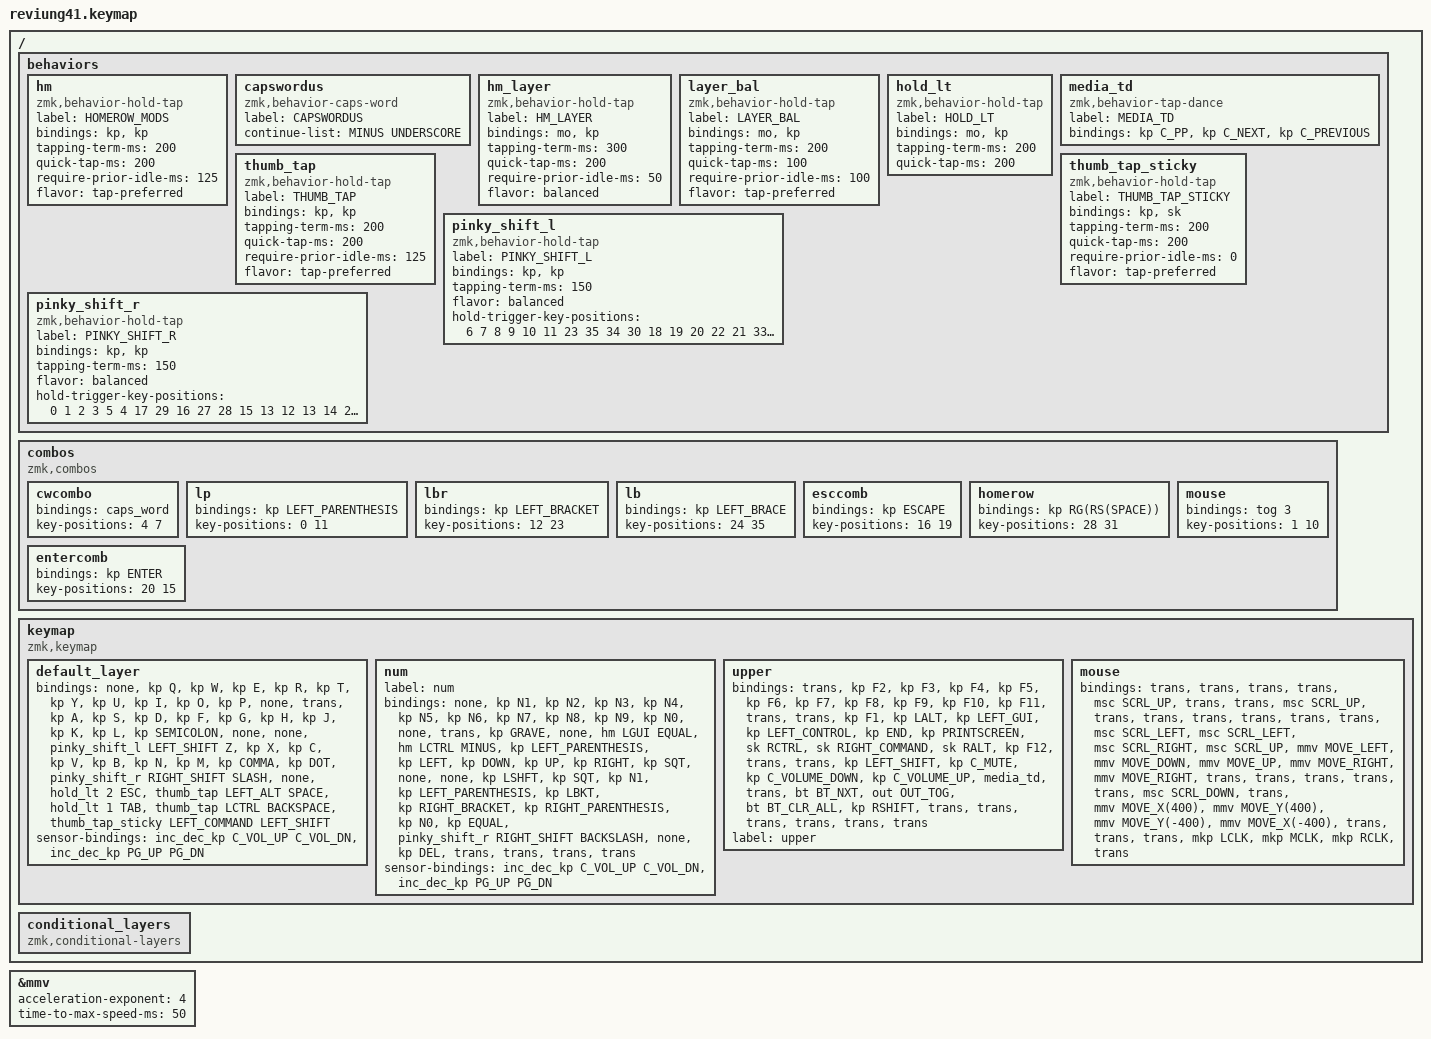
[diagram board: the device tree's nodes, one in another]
/*
 * Copyright (c) 2020 The ZMK Contributors
 *
 * SPDX-License-Identifier: MIT
 */

#define ZMK_POINTING_DEFAULT_MOVE_VAL 1500  // default: 600
#define ZMK_POINTING_DEFAULT_SCRL_VAL 20    // default: 10

#include <behaviors.dtsi>
#include <dt-bindings/zmk/bt.h>
#include <dt-bindings/zmk/keys.h>
#include <dt-bindings/zmk/outputs.h>
#include <dt-bindings/zmk/pointing.h>

&mmv {
    acceleration-exponent = <4>;
    time-to-max-speed-ms = <50>;
};

/ {
    behaviors {
        hm: hm {
            compatible = "zmk,behavior-hold-tap";
            label = "HOMEROW_MODS";
            bindings = <&kp>, <&kp>;

            #binding-cells = <2>;
            tapping-term-ms = <200>;
            quick-tap-ms = <200>;
            require-prior-idle-ms = <125>;
            flavor = "tap-preferred";
        };

        capswordus: capswordus {
            compatible = "zmk,behavior-caps-word";
            label = "CAPSWORDUS";
            #binding-cells = <0>;
            continue-list = <MINUS UNDERSCORE>;
        };

        hm_layer: hm_layer {
            compatible = "zmk,behavior-hold-tap";
            label = "HM_LAYER";
            bindings = <&mo>, <&kp>;

            #binding-cells = <2>;
            tapping-term-ms = <300>;
            quick-tap-ms = <200>;
            require-prior-idle-ms = <50>;
            flavor = "balanced";
        };

        layer_bal: layer_bal {
            compatible = "zmk,behavior-hold-tap";
            label = "LAYER_BAL";
            bindings = <&mo>, <&kp>;

            #binding-cells = <2>;
            tapping-term-ms = <200>;
            quick-tap-ms = <100>;
            require-prior-idle-ms = <100>;
            flavor = "tap-preferred";
        };

        hold_lt: hold_lt {
            compatible = "zmk,behavior-hold-tap";
            label = "HOLD_LT";
            bindings = <&mo>, <&kp>;

            #binding-cells = <2>;
            tapping-term-ms = <200>;
            quick-tap-ms = <200>;
        };

        media_td: media_td {
            compatible = "zmk,behavior-tap-dance";
            label = "MEDIA_TD";
            #binding-cells = <0>;
            bindings = <&kp C_PP>, <&kp C_NEXT>, <&kp C_PREVIOUS>;
        };

        thumb_tap: thumb_tap {
            compatible = "zmk,behavior-hold-tap";
            label = "THUMB_TAP";
            bindings = <&kp>, <&kp>;

            #binding-cells = <2>;
            tapping-term-ms = <200>;
            quick-tap-ms = <200>;
            require-prior-idle-ms = <125>;
            flavor = "tap-preferred";
        };

        thumb_tap_sticky: thumb_tap_sticky {
            compatible = "zmk,behavior-hold-tap";
            label = "THUMB_TAP_STICKY";
            bindings = <&kp>, <&sk>;

            #binding-cells = <2>;
            tapping-term-ms = <200>;
            quick-tap-ms = <200>;
            require-prior-idle-ms = <0>;
            flavor = "tap-preferred";
        };

        pinky_shift_l: pinky_shift_l {
            compatible = "zmk,behavior-hold-tap";
            label = "PINKY_SHIFT_L";
            bindings = <&kp>, <&kp>;

            #binding-cells = <2>;
            tapping-term-ms = <150>;
            flavor = "balanced";
            hold-trigger-key-positions = <6 7 8 9 10 11 23 35 34 30 18 19 20 22 21 33 31 32 28 27>;
        };

        pinky_shift_r: pinky_shift_r {
            compatible = "zmk,behavior-hold-tap";
            label = "PINKY_SHIFT_R";
            bindings = <&kp>, <&kp>;

            #binding-cells = <2>;
            tapping-term-ms = <150>;
            flavor = "balanced";
            hold-trigger-key-positions = <0 1 2 3 5 4 17 29 16 27 28 15 13 12 13 14 26 25 24>;
        };
    };

    combos {
        compatible = "zmk,combos";

        cwcombo {
            bindings = <&caps_word>;
            key-positions = <4 7>;
        };

        lp {
            bindings = <&kp LEFT_PARENTHESIS>;
            key-positions = <0 11>;
        };

        lbr {
            bindings = <&kp LEFT_BRACKET>;
            key-positions = <12 23>;
        };

        lb {
            bindings = <&kp LEFT_BRACE>;
            key-positions = <24 35>;
        };

        esccomb {
            bindings = <&kp ESCAPE>;
            key-positions = <16 19>;
        };

        homerow {
            bindings = <&kp RG(RS(SPACE))>;
            key-positions = <28 31>;
        };

        mouse {
            bindings = <&tog 3>;
            key-positions = <1 10>;
        };

        entercomb {
            bindings = <&kp ENTER>;
            key-positions = <20 15>;
        };
    };

    keymap {
        compatible = "zmk,keymap";

        default_layer {
            // ---------------------------------------------------------------------------------------------------------------------------------
            // |  ESC  |  Q  |  W  |  E   |  R   |  T   |                                          |  Y   |  U    |  I    |  O   |   P   |   \  |
            // |  TAB  |  A  |  S  |  D   |  F   |  G   |                                          |  H   |  J    |  K    |  L   |   ;   |   '  |
            // | SHIFT |  Z  |  X  |  C   |  V   |  B   | L SHIFT | L SHIFT |  | LAYER 1 | L SHIFT |  N   |  M    |  ,    |  .   |   /   | CTRL |
            //                     | GUI  | DEL  | RET  |  SPACE  |   ESC   |  |   RET   |  SPACE  | TAB  | BSPC  | R-ALT |

            bindings = <
&none  &kp Q  &kp W  &kp E  &kp R  &kp T  &kp Y  &kp U  &kp I  &kp O  &kp P  &none  &trans  &kp A  &kp S  &kp D  &kp F  &kp G  &kp H  &kp J  &kp K  &kp L  &kp SEMICOLON  &none  &none  &pinky_shift_l LEFT_SHIFT Z  &kp X  &kp C  &kp V  &kp B  &kp N  &kp M  &kp COMMA  &kp DOT  &pinky_shift_r RIGHT_SHIFT SLASH  &none  &hold_lt 2 ESC  &thumb_tap LEFT_ALT SPACE  &hold_lt 1 TAB  &thumb_tap LCTRL BACKSPACE  &thumb_tap_sticky LEFT_COMMAND LEFT_SHIFT
            >;

            sensor-bindings = <&inc_dec_kp C_VOL_UP C_VOL_DN &inc_dec_kp PG_UP PG_DN>;
        };

        num {
            label = "num";
            bindings = <
&none  &kp N1  &kp N2  &kp N3  &kp N4  &kp N5  &kp N6  &kp N7  &kp N8  &kp N9  &kp N0  &none  &trans  &kp GRAVE  &none  &hm LGUI EQUAL  &hm LCTRL MINUS  &kp LEFT_PARENTHESIS  &kp LEFT  &kp DOWN  &kp UP  &kp RIGHT  &kp SQT  &none  &none  &kp LSHFT  &kp SQT  &kp N1  &kp LEFT_PARENTHESIS  &kp LBKT  &kp RIGHT_BRACKET  &kp RIGHT_PARENTHESIS  &kp N0  &kp EQUAL  &pinky_shift_r RIGHT_SHIFT BACKSLASH  &none  &kp DEL  &trans  &trans  &trans  &trans
            >;

            sensor-bindings =
                <&inc_dec_kp C_VOL_UP C_VOL_DN>,
                <&inc_dec_kp PG_UP PG_DN>;
        };

        upper {
            bindings = <
&trans  &kp F2  &kp F3  &kp F4  &kp F5  &kp F6  &kp F7  &kp F8  &kp F9  &kp F10  &kp F11  &trans  &trans  &kp F1  &kp LALT  &kp LEFT_GUI  &kp LEFT_CONTROL  &kp END  &kp PRINTSCREEN  &sk RCTRL  &sk RIGHT_COMMAND  &sk RALT  &kp F12  &trans  &trans  &kp LEFT_SHIFT  &kp C_MUTE  &kp C_VOLUME_DOWN  &kp C_VOLUME_UP  &media_td  &trans  &bt BT_NXT  &out OUT_TOG  &bt BT_CLR_ALL  &kp RSHIFT  &trans  &trans  &trans  &trans  &trans  &trans
            >;

            label = "upper";
        };

        mouse {
            bindings = <
&trans  &trans  &trans  &trans  &msc SCRL_UP  &trans  &trans  &msc SCRL_UP  &trans  &trans  &trans  &trans  &trans  &trans  &msc SCRL_LEFT  &msc SCRL_LEFT  &msc SCRL_RIGHT  &msc SCRL_UP  &mmv MOVE_LEFT  &mmv MOVE_DOWN  &mmv MOVE_UP  &mmv MOVE_RIGHT  &mmv MOVE_RIGHT  &trans  &trans  &trans  &trans  &trans  &msc SCRL_DOWN  &trans  &mmv MOVE_X(400)  &mmv MOVE_Y(400)  &mmv MOVE_Y(-400)  &mmv MOVE_X(-400)  &trans  &trans  &trans  &mkp LCLK  &mkp MCLK  &mkp RCLK  &trans
            >;
        };
    };

    conditional_layers { compatible = "zmk,conditional-layers"; };
};
